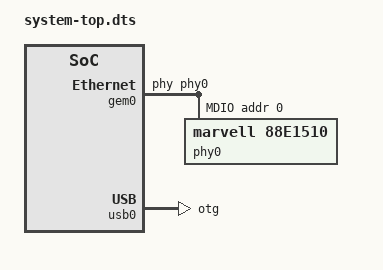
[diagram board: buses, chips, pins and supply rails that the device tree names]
/dts-v1/;
/include/ "system-conf.dtsi"
/ {
};

&gem0 {
	phy-handle = <&phy0>;
	ps7_ethernet_0_mdio: mdio {
		#address-cells = <1>;
		#size-cells = <0>;
		phy0: phy@0 {
			compatible = "marvell,88e1510";
			device_type = "ethernet-phy";
			reg = <0>;
		} ;
	} ;
};

&flash0 {
	compatible = "spansion,s25fl256s1";
};

&usb0 {
	dr_mode = "otg";
} ;
